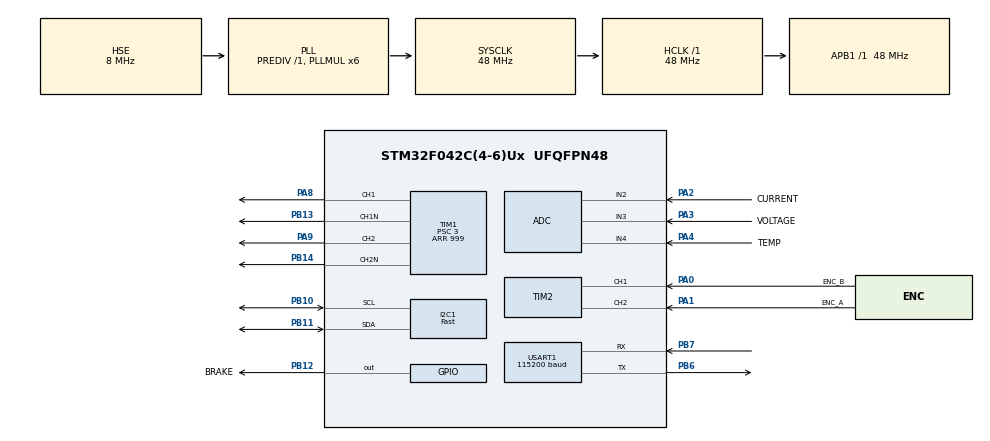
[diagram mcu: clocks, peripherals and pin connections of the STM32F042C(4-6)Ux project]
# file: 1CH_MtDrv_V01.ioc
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ADC.ClockPrescaler=ADC_CLOCK_SYNC_PCLK_DIV4
ADC.ContinuousConvMode=ENABLE
ADC.SamplingTime=ADC_SAMPLETIME_239CYCLES_5
Dma.ADC.1.Direction=DMA_PERIPH_TO_MEMORY
Dma.ADC.1.Instance=DMA1_Channel1
Dma.ADC.1.MemDataAlignment=DMA_MDATAALIGN_WORD
Dma.ADC.1.MemInc=DMA_MINC_ENABLE
Dma.ADC.1.Mode=DMA_NORMAL
Dma.ADC.1.PeriphDataAlignment=DMA_PDATAALIGN_WORD
Dma.ADC.1.PeriphInc=DMA_PINC_DISABLE
Dma.ADC.1.Priority=DMA_PRIORITY_LOW
Dma.Request0=USART1_RX
Dma.Request1=ADC
Dma.USART1_RX.0.Direction=DMA_PERIPH_TO_MEMORY
Dma.USART1_RX.0.Instance=DMA1_Channel3
Dma.USART1_RX.0.MemDataAlignment=DMA_MDATAALIGN_BYTE
Dma.USART1_RX.0.MemInc=DMA_MINC_ENABLE
Dma.USART1_RX.0.Mode=DMA_NORMAL
Dma.USART1_RX.0.PeriphDataAlignment=DMA_PDATAALIGN_BYTE
Dma.USART1_RX.0.PeriphInc=DMA_PINC_DISABLE
Dma.USART1_RX.0.Priority=DMA_PRIORITY_MEDIUM
I2C1.I2C_Fall_Time=50
I2C1.I2C_Rise_Time=50
I2C1.I2C_Speed_Mode=I2C_Fast
I2C1.Timing=0x00701850
Mcu.Family=STM32F0
Mcu.Name=STM32F042C(4-6)Ux
Mcu.Package=UFQFPN48
NVIC.DMA1_Channel1_IRQn=true\:0\:0\:false\:false\:true\:false\:true\:true
NVIC.DMA1_Channel2_3_IRQn=true\:0\:0\:false\:false\:true\:false\:true\:true
NVIC.TIM2_IRQn=true\:0\:0\:false\:false\:true\:true\:true\:true
NVIC.USART1_IRQn=true\:0\:0\:false\:false\:true\:true\:true\:true
PA0.GPIO_Label=ENC_B
PA0.Signal=S_TIM2_CH1_ETR
PA1.GPIO_Label=ENC_A
PA1.Signal=S_TIM2_CH2
PA13.Mode=Serial_Wire
PA13.Signal=SYS_SWDIO
PA14.Mode=Serial_Wire
PA14.Signal=SYS_SWCLK
PA2.GPIO_Label=CURRENT
PA2.Mode=IN2
PA2.Signal=ADC_IN2
PA3.GPIO_Label=VOLTAGE
PA3.Mode=IN3
PA3.Signal=ADC_IN3
PA4.GPIO_Label=TEMP
PA4.Mode=IN4
PA4.Signal=ADC_IN4
PA8.Signal=S_TIM1_CH1
PA9.Signal=S_TIM1_CH2
PB10.Mode=I2C
PB10.Signal=I2C1_SCL
PB11.Mode=I2C
PB11.Signal=I2C1_SDA
PB12.GPIO_Label=BRAKE
PB12.Signal=GPIO_Output
PB13.Mode=PWM Generation1 CH1 CH1N
PB13.Signal=TIM1_CH1N
PB14.Mode=PWM Generation2 CH2 CH2N
PB14.Signal=TIM1_CH2N
PB6.Mode=Asynchronous
PB6.Signal=USART1_TX
PB7.Mode=Asynchronous
PB7.Signal=USART1_RX
PC14OSC32_IN.GPIO_Label=RUN
PC14OSC32_IN.Signal=GPIO_Output
PC15OSC32_OUT.GPIO_Label=FAULT
PC15OSC32_OUT.Signal=GPIO_Output
PF0-OSC_IN.Mode=HSE-External-Oscillator
PF0-OSC_IN.Signal=RCC_OSC_IN
PF1-OSC_OUT.Mode=HSE-External-Oscillator
PF1-OSC_OUT.Signal=RCC_OSC_OUT
ProjectManager.HeapSize=0x200
ProjectManager.StackSize=0x400
ProjectManager.TargetToolchain=STM32CubeIDE
RCC.AHBFreq_Value=48000000
RCC.APB1Freq_Value=48000000
RCC.APB1TimFreq_Value=48000000
RCC.HCLKFreq_Value=48000000
RCC.I2c1ClockSelection=RCC_I2C1CLKSOURCE_SYSCLK
RCC.PLLMUL=RCC_PLL_MUL6
RCC.PLLSourceVirtual=RCC_PLLSOURCE_HSE
RCC.SYSCLKFreq_VALUE=48000000
RCC.SYSCLKSource=RCC_SYSCLKSOURCE_PLLCLK
SH.S_TIM1_CH1.0=TIM1_CH1,PWM Generation1 CH1 CH1N
SH.S_TIM1_CH2.0=TIM1_CH2,PWM Generation2 CH2 CH2N
SH.S_TIM2_CH1_ETR.0=TIM2_CH1,Encoder_Interface
SH.S_TIM2_CH2.0=TIM2_CH2,Encoder_Interface
TIM1.Channel-PWM\ Generation1\ CH1\ CH1N=TIM_CHANNEL_1
TIM1.Channel-PWM\ Generation2\ CH2\ CH2N=TIM_CHANNEL_2
TIM1.DeadTime=50
TIM1.OCNIdleState_1=TIM_OCNIDLESTATE_SET
TIM1.OCNIdleState_2=TIM_OCNIDLESTATE_SET
TIM1.Period=999
TIM1.Prescaler=3
TIM1.Pulse-PWM\ Generation1\ CH1\ CH1N=999
TIM1.Pulse-PWM\ Generation2\ CH2\ CH2N=999
USART1.BaudRate=115200
USART1.VirtualMode-Asynchronous=VM_ASYNC
board=custom

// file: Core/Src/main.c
/* USER CODE BEGIN Header */
/**
  ******************************************************************************
  * @file           : main.c
  * @brief          : Main program body
  ******************************************************************************
  * @attention
  *
  * Copyright (c) 2024 STMicroelectronics.
  * All rights reserved.
  *
  * This software is licensed under terms that can be found in the LICENSE file
  * in the root directory of this software component.
  * If no LICENSE file comes with this software, it is provided AS-IS.
  *
  ******************************************************************************
  */
/* USER CODE END Header */
#include "main.h"
#include "adc.h"
#include "dma.h"
#include "i2c.h"
#include "tim.h"
#include "usart.h"
#include "gpio.h"

/* USER CODE BEGIN Includes */
#include "../../Drivers/1CH_MtDrv_V01/App.h"
/* USER CODE END Includes */

void SystemClock_Config(void);

int main(void)
{

  /* MCU Configuration--------------------------------------------------------*/

  /* Reset of all peripherals, Initializes the Flash interface and the Systick. */
  HAL_Init();

  /* Configure the system clock */
  SystemClock_Config();

  /* Initialize all configured peripherals */
  MX_GPIO_Init();
  MX_DMA_Init();
  MX_TIM1_Init();
  MX_I2C1_Init();
  MX_TIM2_Init();
  MX_USART1_UART_Init();
  MX_ADC_Init();
  /* USER CODE BEGIN 2 */
  MtDrv_Main();
  /* USER CODE END 2 */

  /* Infinite loop */
  while (1)
  {

  }
}

void SystemClock_Config(void)
{
  RCC_OscInitTypeDef RCC_OscInitStruct = {0};
  RCC_ClkInitTypeDef RCC_ClkInitStruct = {0};
  RCC_PeriphCLKInitTypeDef PeriphClkInit = {0};

  /** Initializes the RCC Oscillators according to the specified parameters
  * in the RCC_OscInitTypeDef structure.
  */
  RCC_OscInitStruct.OscillatorType = RCC_OSCILLATORTYPE_HSE;
  RCC_OscInitStruct.HSEState = RCC_HSE_ON;
  RCC_OscInitStruct.PLL.PLLState = RCC_PLL_ON;
  RCC_OscInitStruct.PLL.PLLSource = RCC_PLLSOURCE_HSE;
  RCC_OscInitStruct.PLL.PLLMUL = RCC_PLL_MUL6;
  RCC_OscInitStruct.PLL.PREDIV = RCC_PREDIV_DIV1;
  if (HAL_RCC_OscConfig(&RCC_OscInitStruct) != HAL_OK)
  {
    Error_Handler();
  }

  /** Initializes the CPU, AHB and APB buses clocks
  */
  RCC_ClkInitStruct.ClockType = RCC_CLOCKTYPE_HCLK|RCC_CLOCKTYPE_SYSCLK
                              |RCC_CLOCKTYPE_PCLK1;
  RCC_ClkInitStruct.SYSCLKSource = RCC_SYSCLKSOURCE_PLLCLK;
  RCC_ClkInitStruct.AHBCLKDivider = RCC_SYSCLK_DIV1;
  RCC_ClkInitStruct.APB1CLKDivider = RCC_HCLK_DIV1;

  if (HAL_RCC_ClockConfig(&RCC_ClkInitStruct, FLASH_LATENCY_1) != HAL_OK)
  {
    Error_Handler();
  }
  PeriphClkInit.PeriphClockSelection = RCC_PERIPHCLK_USART1|RCC_PERIPHCLK_I2C1;
  PeriphClkInit.Usart1ClockSelection = RCC_USART1CLKSOURCE_PCLK1;
  PeriphClkInit.I2c1ClockSelection = RCC_I2C1CLKSOURCE_SYSCLK;
  if (HAL_RCCEx_PeriphCLKConfig(&PeriphClkInit) != HAL_OK)
  {
    Error_Handler();
  }
}

void Error_Handler(void)
{
  __disable_irq();
  while (1)
  {
  }
}
